# STM32WB35CCU6A register map
File version: 1.0
Registers are 32-bit, access not given, reset 0x0 unless marked. A register's access mark holds for its fields unless they carry their own. Offsets are from the block's base; [hi:lo] are bit positions; 'fields as' and 'values as' point back to an identical list.

## RCC
Base 0x58000000
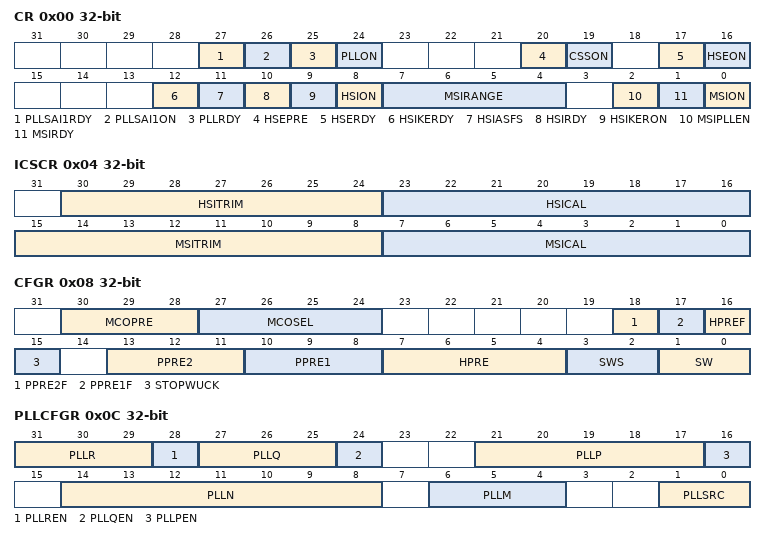
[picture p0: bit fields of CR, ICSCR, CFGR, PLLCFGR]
0x00 CR
  [27] PLLSAI1RDY, [26] PLLSAI1ON, [25] PLLRDY, [24] PLLON, [20] HSEPRE, [19] CSSON, [17] HSERDY, [16] HSEON, [12] HSIKERDY, [11] HSIASFS, [10] HSIRDY, [9] HSIKERON, [8] HSION, [7:4] MSIRANGE, [2] MSIPLLEN, [1] MSIRDY, [0] MSION
0x04 ICSCR
  [30:24] HSITRIM, [23:16] HSICAL, [15:8] MSITRIM, [7:0] MSICAL
0x08 CFGR
  [30:28] MCOPRE, [27:24] MCOSEL, [18] PPRE2F, [17] PPRE1F, [16] HPREF, [15] STOPWUCK, [13:11] PPRE2, [10:8] PPRE1, [7:4] HPRE, [3:2] SWS, [1:0] SW
0x0C PLLCFGR
  [31:29] PLLR, [28] PLLREN, [27:25] PLLQ, [24] PLLQEN, [21:17] PLLP, [16] PLLPEN, [14:8] PLLN, [6:4] PLLM, [1:0] PLLSRC
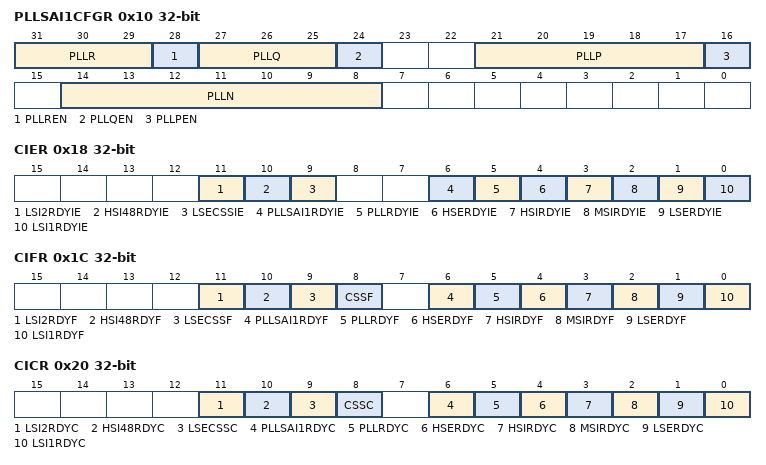
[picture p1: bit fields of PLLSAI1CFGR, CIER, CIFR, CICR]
0x10 PLLSAI1CFGR
  [31:29] PLLR, [28] PLLREN, [27:25] PLLQ, [24] PLLQEN, [21:17] PLLP, [16] PLLPEN, [14:8] PLLN
0x18 CIER
  [11] LSI2RDYIE, [10] HSI48RDYIE, [9] LSECSSIE, [6] PLLSAI1RDYIE, [5] PLLRDYIE, [4] HSERDYIE, [3] HSIRDYIE, [2] MSIRDYIE, [1] LSERDYIE, [0] LSI1RDYIE
0x1C CIFR
  [11] LSI2RDYF, [10] HSI48RDYF, [9] LSECSSF, [8] CSSF, [6] PLLSAI1RDYF, [5] PLLRDYF, [4] HSERDYF, [3] HSIRDYF, [2] MSIRDYF, [1] LSERDYF, [0] LSI1RDYF
0x20 CICR
  [11] LSI2RDYC, [10] HSI48RDYC, [9] LSECSSC, [8] CSSC, [6] PLLSAI1RDYC, [5] PLLRDYC, [4] HSERDYC, [3] HSIRDYC, [2] MSIRDYC, [1] LSERDYC, [0] LSI1RDYC
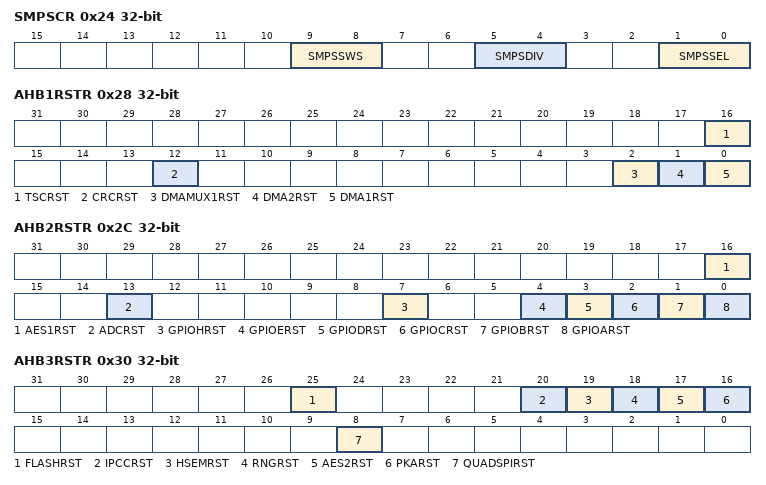
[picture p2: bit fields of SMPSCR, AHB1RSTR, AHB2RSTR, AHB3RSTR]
0x24 SMPSCR
  [9:8] SMPSSWS, [5:4] SMPSDIV, [1:0] SMPSSEL
0x28 AHB1RSTR
  [16] TSCRST, [12] CRCRST, [2] DMAMUX1RST, [1] DMA2RST, [0] DMA1RST
0x2C AHB2RSTR
  [16] AES1RST, [13] ADCRST, [7] GPIOHRST, [4] GPIOERST, [3] GPIODRST, [2] GPIOCRST, [1] GPIOBRST, [0] GPIOARST
0x30 AHB3RSTR
  [25] FLASHRST, [20] IPCCRST, [19] HSEMRST, [18] RNGRST, [17] AES2RST, [16] PKARST, [8] QUADSPIRST
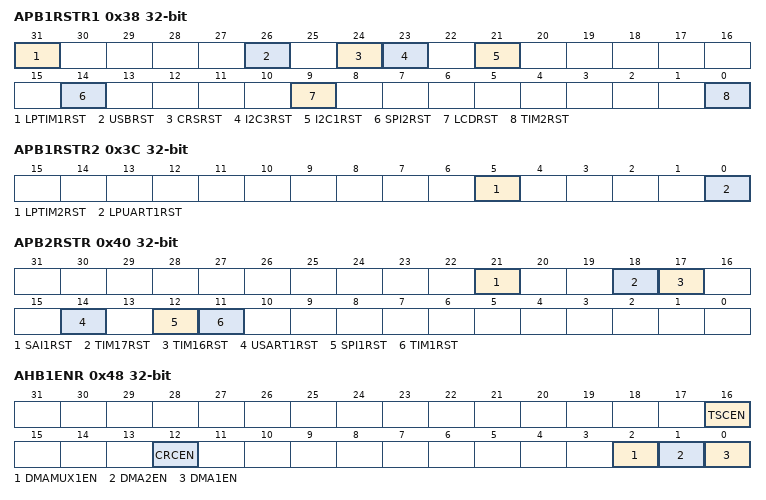
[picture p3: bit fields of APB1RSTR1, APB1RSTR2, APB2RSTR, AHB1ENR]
0x38 APB1RSTR1
  [31] LPTIM1RST, [26] USBRST, [24] CRSRST, [23] I2C3RST, [21] I2C1RST, [14] SPI2RST, [9] LCDRST, [0] TIM2RST
0x3C APB1RSTR2
  [5] LPTIM2RST, [0] LPUART1RST
0x40 APB2RSTR
  [21] SAI1RST, [18] TIM17RST, [17] TIM16RST, [14] USART1RST, [12] SPI1RST, [11] TIM1RST
0x44 APB3RSTR
  [0] RFRST
0x48 AHB1ENR
  [16] TSCEN, [12] CRCEN, [2] DMAMUX1EN, [1] DMA2EN, [0] DMA1EN
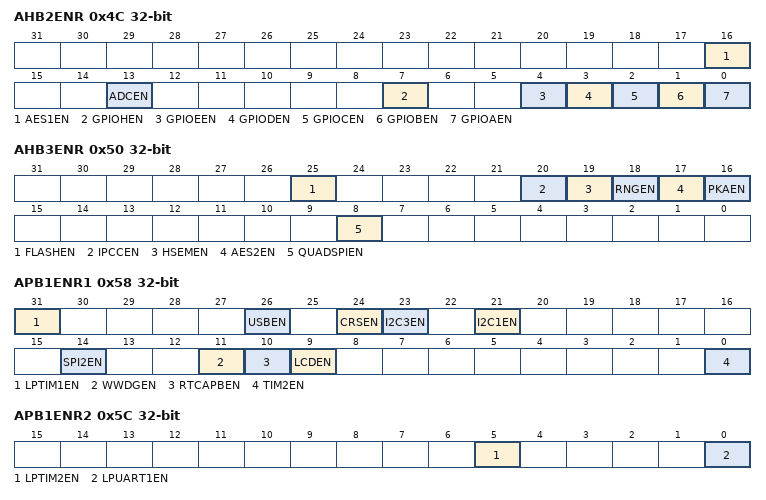
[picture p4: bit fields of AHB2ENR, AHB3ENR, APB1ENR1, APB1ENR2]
0x4C AHB2ENR
  [16] AES1EN, [13] ADCEN, [7] GPIOHEN, [4] GPIOEEN, [3] GPIODEN, [2] GPIOCEN, [1] GPIOBEN, [0] GPIOAEN
0x50 AHB3ENR
  [25] FLASHEN, [20] IPCCEN, [19] HSEMEN, [18] RNGEN, [17] AES2EN, [16] PKAEN, [8] QUADSPIEN
0x58 APB1ENR1
  [31] LPTIM1EN, [26] USBEN, [24] CRSEN, [23] I2C3EN, [21] I2C1EN, [14] SPI2EN, [11] WWDGEN, [10] RTCAPBEN, [9] LCDEN, [0] TIM2EN
0x5C APB1ENR2
  [5] LPTIM2EN, [0] LPUART1EN
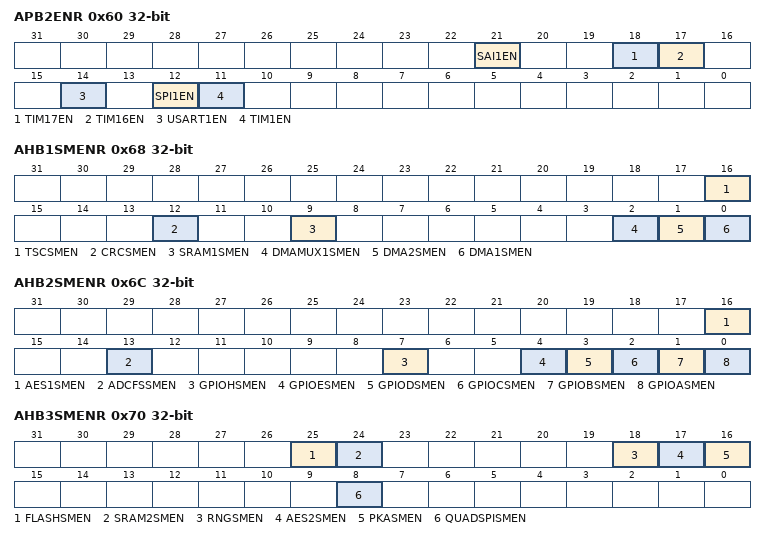
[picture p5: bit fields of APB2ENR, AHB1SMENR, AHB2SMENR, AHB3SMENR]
0x60 APB2ENR
  [21] SAI1EN, [18] TIM17EN, [17] TIM16EN, [14] USART1EN, [12] SPI1EN, [11] TIM1EN
0x68 AHB1SMENR
  [16] TSCSMEN, [12] CRCSMEN, [9] SRAM1SMEN, [2] DMAMUX1SMEN, [1] DMA2SMEN, [0] DMA1SMEN
0x6C AHB2SMENR
  [16] AES1SMEN, [13] ADCFSSMEN, [7] GPIOHSMEN, [4] GPIOESMEN, [3] GPIODSMEN, [2] GPIOCSMEN, [1] GPIOBSMEN, [0] GPIOASMEN
0x70 AHB3SMENR
  [25] FLASHSMEN, [24] SRAM2SMEN, [18] RNGSMEN, [17] AES2SMEN, [16] PKASMEN, [8] QUADSPISMEN
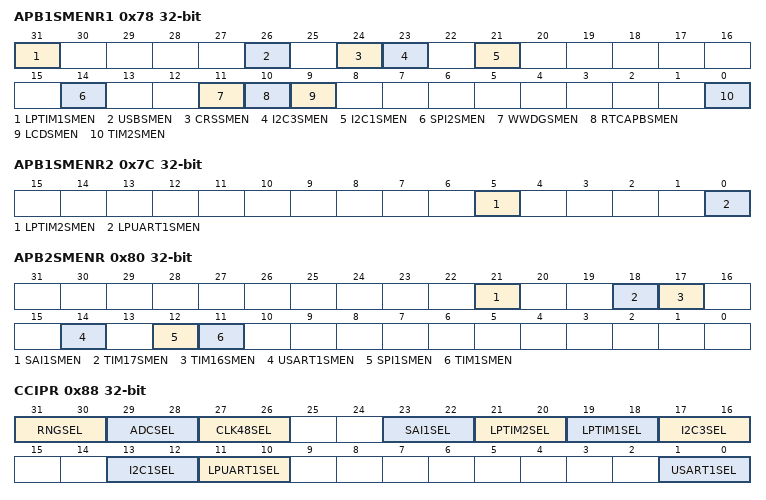
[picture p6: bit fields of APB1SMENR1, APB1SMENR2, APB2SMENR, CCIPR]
0x78 APB1SMENR1
  [31] LPTIM1SMEN, [26] USBSMEN, [24] CRSSMEN, [23] I2C3SMEN, [21] I2C1SMEN, [14] SPI2SMEN, [11] WWDGSMEN, [10] RTCAPBSMEN, [9] LCDSMEN, [0] TIM2SMEN
0x7C APB1SMENR2
  [5] LPTIM2SMEN, [0] LPUART1SMEN
0x80 APB2SMENR
  [21] SAI1SMEN, [18] TIM17SMEN, [17] TIM16SMEN, [14] USART1SMEN, [12] SPI1SMEN, [11] TIM1SMEN
0x88 CCIPR
  [31:30] RNGSEL, [29:28] ADCSEL, [27:26] CLK48SEL, [23:22] SAI1SEL, [21:20] LPTIM2SEL, [19:18] LPTIM1SEL, [17:16] I2C3SEL, [13:12] I2C1SEL, [11:10] LPUART1SEL, [1:0] USART1SEL
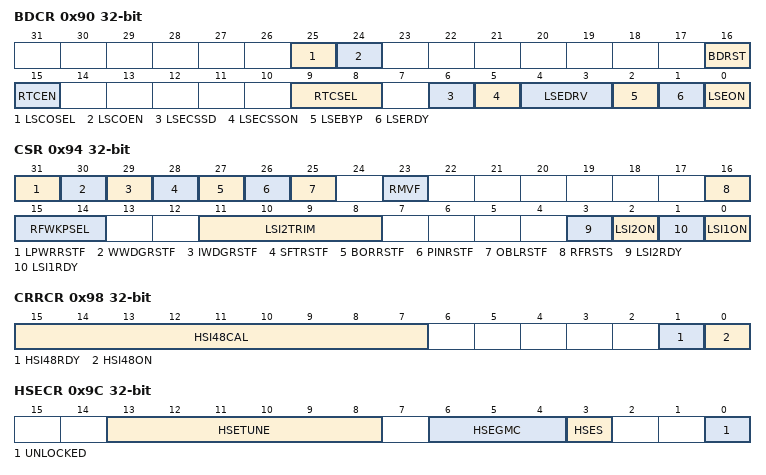
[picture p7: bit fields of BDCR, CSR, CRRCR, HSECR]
0x90 BDCR
  [25] LSCOSEL, [24] LSCOEN, [16] BDRST, [15] RTCEN, [9:8] RTCSEL, [6] LSECSSD, [5] LSECSSON, [4:3] LSEDRV, [2] LSEBYP, [1] LSERDY, [0] LSEON
0x94 CSR
  [31] LPWRRSTF, [30] WWDGRSTF, [29] IWDGRSTF, [28] SFTRSTF, [27] BORRSTF, [26] PINRSTF, [25] OBLRSTF, [23] RMVF, [16] RFRSTS, [15:14] RFWKPSEL, [11:8] LSI2TRIM, [3] LSI2RDY, [2] LSI2ON, [1] LSI1RDY, [0] LSI1ON
0x98 CRRCR
  [15:7] HSI48CAL, [1] HSI48RDY, [0] HSI48ON
0x9C HSECR
  [13:8] HSETUNE, [6:4] HSEGMC, [3] HSES, [0] UNLOCKED
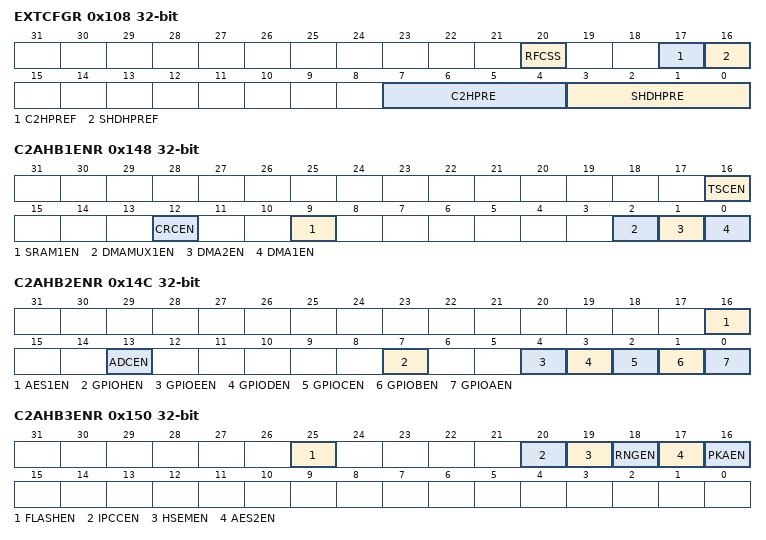
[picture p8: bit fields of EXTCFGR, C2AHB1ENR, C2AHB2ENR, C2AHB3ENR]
0x108 EXTCFGR
  [20] RFCSS, [17] C2HPREF, [16] SHDHPREF, [7:4] C2HPRE, [3:0] SHDHPRE
0x148 C2AHB1ENR
  [16] TSCEN, [12] CRCEN, [9] SRAM1EN, [2] DMAMUX1EN, [1] DMA2EN, [0] DMA1EN
0x14C C2AHB2ENR
  fields as AHB2ENR
0x150 C2AHB3ENR
  [25] FLASHEN, [20] IPCCEN, [19] HSEMEN, [18] RNGEN, [17] AES2EN, [16] PKAEN
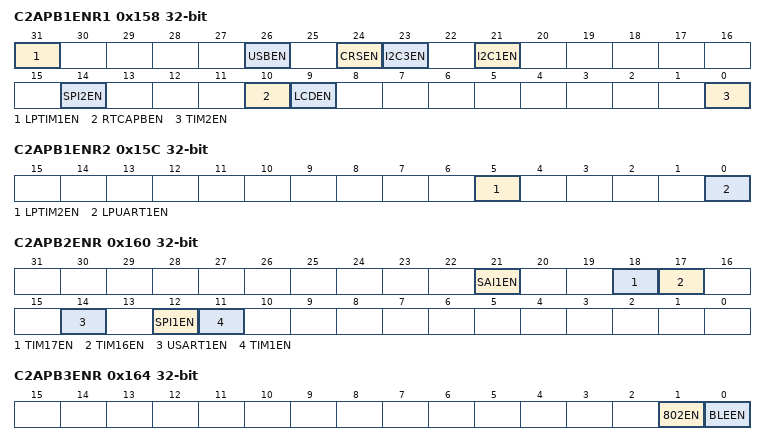
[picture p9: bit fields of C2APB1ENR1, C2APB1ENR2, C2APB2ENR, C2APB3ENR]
0x158 C2APB1ENR1
  [31] LPTIM1EN, [26] USBEN, [24] CRSEN, [23] I2C3EN, [21] I2C1EN, [14] SPI2EN, [10] RTCAPBEN, [9] LCDEN, [0] TIM2EN
0x15C C2APB1ENR2
  [5] LPTIM2EN, [0] LPUART1EN
0x160 C2APB2ENR
  fields as APB2ENR
0x164 C2APB3ENR
  [1] 802EN, [0] BLEEN
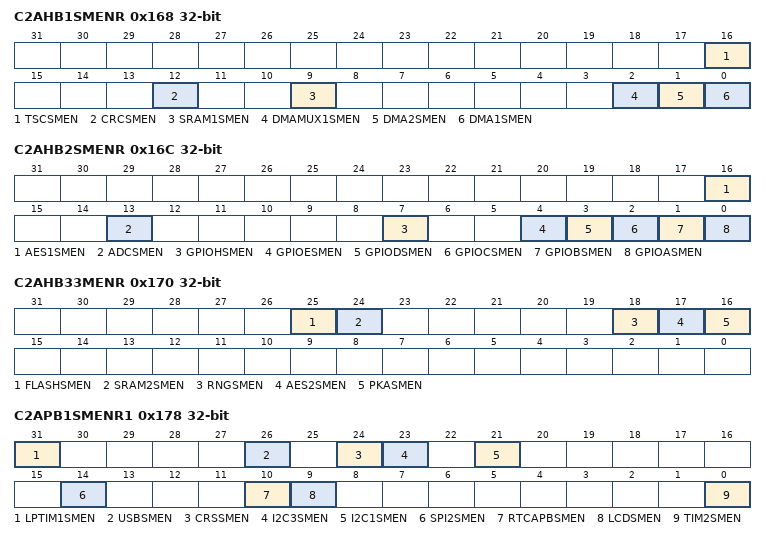
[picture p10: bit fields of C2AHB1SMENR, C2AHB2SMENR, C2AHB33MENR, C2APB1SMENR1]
0x168 C2AHB1SMENR
  fields as AHB1SMENR
0x16C C2AHB2SMENR
  [16] AES1SMEN, [13] ADCSMEN, [7] GPIOHSMEN, [4] GPIOESMEN, [3] GPIODSMEN, [2] GPIOCSMEN, [1] GPIOBSMEN, [0] GPIOASMEN
0x170 C2AHB33MENR
  [25] FLASHSMEN, [24] SRAM2SMEN, [18] RNGSMEN, [17] AES2SMEN, [16] PKASMEN
0x178 C2APB1SMENR1
  [31] LPTIM1SMEN, [26] USBSMEN, [24] CRSSMEN, [23] I2C3SMEN, [21] I2C1SMEN, [14] SPI2SMEN, [10] RTCAPBSMEN, [9] LCDSMEN, [0] TIM2SMEN
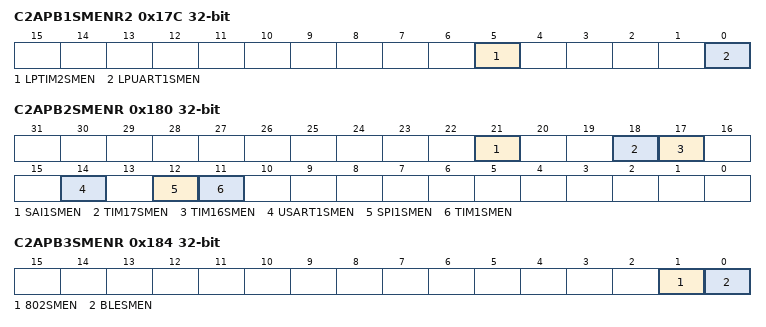
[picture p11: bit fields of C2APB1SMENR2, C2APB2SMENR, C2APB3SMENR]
0x17C C2APB1SMENR2
  [5] LPTIM2SMEN, [0] LPUART1SMEN
0x180 C2APB2SMENR
  fields as APB2SMENR
0x184 C2APB3SMENR
  [1] 802SMEN, [0] BLESMEN
